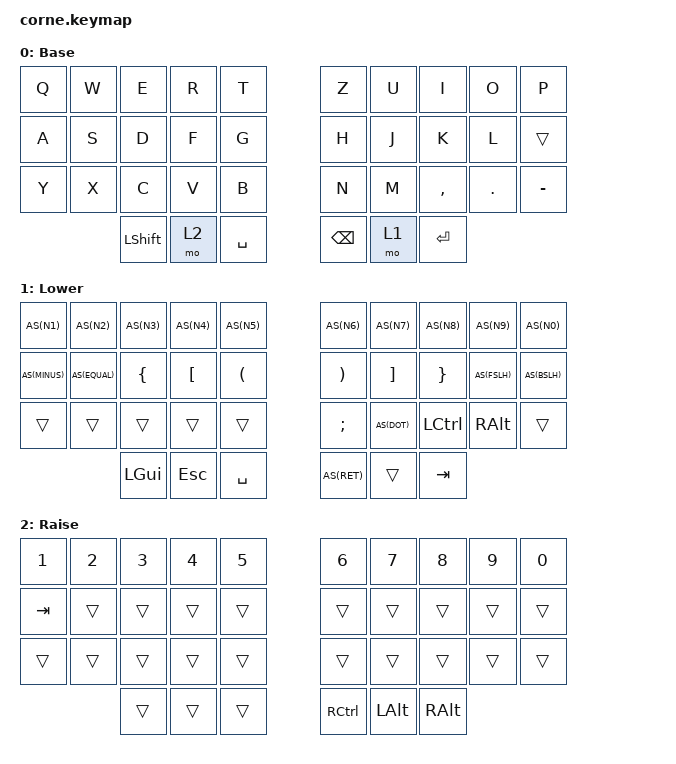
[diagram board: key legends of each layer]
/*
 * Copyright (c) 2020 The ZMK Contributors
 *
 * SPDX-License-Identifier: MIT
 */

#include <behaviors.dtsi>
#include <dt-bindings/zmk/keys.h>
#include <dt-bindings/zmk/bt.h>


#define AS(keycode) &as LS(keycode) keycode

/ {
    chosen {
      zmk,matrix_transform = &five_column_transform;
    };

    behaviors {
        as: auto_shift {
            compatible = "zmk,behavior-hold-tap";
            #binding-cells = <2>;
            tapping_term_ms = <200>;
            quick_tap_ms = <0>;
            flavor = "tap-preferred";
            bindings = <&kp>, <&kp>;
        };
    };
        keymap {
                compatible = "zmk,keymap";

                default_layer {
                        display-name = "Base";
                        bindings = <

   &kp Q      &kp W      &kp E      &kp R      &kp T              &kp Z      &kp U      &kp I      &kp O     &kp P 
   &kp A      &kp S      &kp D      &kp F      &kp G              &kp H      &kp J      &kp K      &kp L     &trans 
   &kp Y      &kp X      &kp C      &kp V      &kp B              &kp N      &kp M      &kp COMMA  &kp DOT   &kp MINUS
                         &kp LSHIFT &mo 2      &kp SPACE          &kp BSPC   &mo 1      &kp RETURN      

                        >;
                };

// DEFAULT---------------------------------------------------------------------------------------
// |  Q  |  W  |  E  |  R  |  T  |         |  Z  |  U   |  I   |  O   |  P  |
// |  A  |  S  |  D  |  F  |  G  |         |  H  |  J   |  K   |  L   |  ß  | 
// |  Y  |  X  |  C  |  V  |  B  |         |  N  |  M   |  ,   |  .   |  -  |
//             | LSH | RSE | SPC |         | BSPC| LWR  | ENT  |



                lower_layer {
                        display-name = "Lower";
                        bindings = <

   AS(N1)     AS(N2)     AS(N3)     AS(N4)     AS(N5)             AS(N6)     AS(N7)     AS(N8)     AS(N9)    AS(N0)
   AS(MINUS)  AS(EQUAL)  &kp LBRC   &kp LBKT   &kp LPAR           &kp RPAR   &kp RBKT   &kp RBRC   AS(FSLH)  AS(BSLH)
   &trans     &trans     &trans     &trans     &trans             &kp SEMI   AS(DOT)    &kp LCTRL  &kp RALT  &trans
                         &kp LGUI   &kp ESC    &kp SPACE          AS(RET)    &trans     &kp TAB

                        >;
                };

// LOWER-----------------------------------------------------------------------------------------
// |  !  |  "  |  €  |  $  |  %  |         |  &  |  /  |  (  |  )  |  +  |
// |  ?  |  =  |  @  |     |     |         |  {  |  }  |  [  |  ]  |  #  |
// |  <  |  >  |  |  |  '  |  *  |         |  ~  |  \  |  ;  |  :  |  _  |
//             | CAPS| GUI |     |         |     |     |     |



                raise_layer {
                        display-name = "Raise";
                        bindings = <

   &kp N1     &kp N2     &kp N3     &kp N4     &kp N5             &kp N6     &kp N7     &kp N8     &kp N9    &kp N0
   &kp TAB    &trans     &trans     &trans     &trans             &trans     &trans     &trans     &trans    &trans
   &trans     &trans     &trans     &trans     &trans             &trans     &trans     &trans     &trans    &trans
                         &trans     &trans     &trans             &kp RCTRL  &kp LALT   &kp RALT 

                        >;
                };

// RAISE-----------------------------------------------------------------------------------------
// |  1  |  2  |  3  |  4  |  5  |         |  6  |  7  |  8  |  9  |  0  |
// | TAB |     |     |     |     |         |     |     |     |     |     |
// |     |     |     |     |     |         |     |     |     |     |     |
//             |     |     |     |         | STRG| ALT |ALTGR|



        };
};
